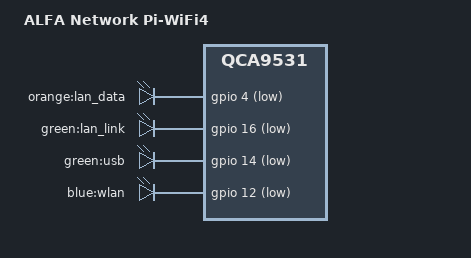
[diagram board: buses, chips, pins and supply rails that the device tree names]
// SPDX-License-Identifier: GPL-2.0-or-later OR MIT

#include "qca9531_alfa-network_r36a.dtsi"

/ {
	model = "ALFA Network Pi-WiFi4";
	compatible = "alfa-network,pi-wifi4", "qca,qca9531";

	aliases {
		led-boot = &led_usb;
		led-failsafe = &led_usb;
		led-upgrade = &led_usb;
	};

	leds {
		compatible = "gpio-leds";

		pinctrl-names = "default";
		pinctrl-0 = <&enable_gpio4 &enable_gpio16>;

		lan_data {
			label = "orange:lan_data";
			gpios = <&gpio 4 GPIO_ACTIVE_LOW>;
		};

		lan_link {
			label = "green:lan_link";
			gpios = <&gpio 16 GPIO_ACTIVE_LOW>;
		};

		led_usb: usb {
			label = "green:usb";
			gpios = <&gpio 14 GPIO_ACTIVE_LOW>;
			linux,default-trigger = "usbport";
			trigger-sources = <&gl850g_port1>, <&gl850g_port2>,
					  <&gl850g_port3>, <&gl850g_port4>;
		};

		wlan {
			label = "blue:wlan";
			gpios = <&gpio 12 GPIO_ACTIVE_LOW>;
			linux,default-trigger = "phy0tpt";
		};
	};
};

&eth0 {
	mtd-mac-address = <&art 0x1002>;
	mtd-mac-address-increment = <(-1)>;
};

&eth1 {
	compatible = "syscon", "simple-mfd";
};

&gpio_export {
	usb-power {
		gpio-export,name = "usb-power";
		gpio-export,output = <1>;
		gpios = <&gpio 3 GPIO_ACTIVE_HIGH>;
	};
};

&hub_port0 {
	#address-cells = <1>;
	#size-cells = <0>;

	gl850g_port1: port@1 {
		reg = <1>;
		#trigger-source-cells = <0>;
	};

	gl850g_port2: port@2 {
		reg = <2>;
		#trigger-source-cells = <0>;
	};

	gl850g_port3: port@3 {
		reg = <3>;
		#trigger-source-cells = <0>;
	};

	gl850g_port4: port@4 {
		reg = <4>;
		#trigger-source-cells = <0>;
	};
};
